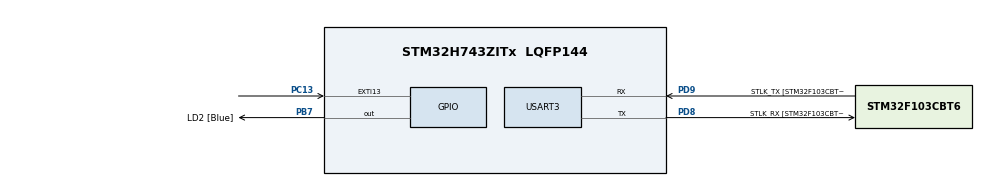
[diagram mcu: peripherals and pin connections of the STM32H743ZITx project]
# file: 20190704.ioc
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Mcu.Family=STM32H7
Mcu.Name=STM32H743ZITx
Mcu.Package=LQFP144
NVIC.EXTI15_10_IRQn=true\:1\:0\:true\:false\:true\:true\:true
NVIC.PriorityGroup=NVIC_PRIORITYGROUP_4
NVIC.TIM3_IRQn=true\:2\:0\:true\:false\:true\:true\:true
PA13\ (JTMS/SWDIO).Mode=Serial_Wire
PA13\ (JTMS/SWDIO).Signal=DEBUG_JTMS-SWDIO
PA14\ (JTCK/SWCLK).Mode=Serial_Wire
PA14\ (JTCK/SWCLK).Signal=DEBUG_JTCK-SWCLK
PB7.GPIO_Label=LD2 [Blue]
PB7.Signal=GPIO_Output
PC13.Signal=GPXTI13
PC14-OSC32_IN\ (OSC32_IN).Mode=LSE-External-Oscillator
PC14-OSC32_IN\ (OSC32_IN).Signal=RCC_OSC32_IN
PC15-OSC32_OUT\ (OSC32_OUT).Mode=LSE-External-Oscillator
PC15-OSC32_OUT\ (OSC32_OUT).Signal=RCC_OSC32_OUT
PD8.GPIO_Label=STLK_RX [STM32F103CBT6_PA3]
PD8.Mode=Asynchronous
PD8.Signal=USART3_TX
PD9.GPIO_Label=STLK_TX [STM32F103CBT6_PA2]
PD9.Mode=Asynchronous
PD9.Signal=USART3_RX
PH0-OSC_IN\ (PH0).GPIO_Label=MCO
PH0-OSC_IN\ (PH0).Mode=HSE-External-Clock-Source
PH0-OSC_IN\ (PH0).Signal=RCC_OSC_IN
PH1-OSC_OUT\ (PH1).Mode=HSE-External-Clock-Source
PH1-OSC_OUT\ (PH1).Signal=RCC_OSC_OUT
ProjectManager.HeapSize=0x200
ProjectManager.StackSize=0x400
ProjectManager.TargetToolchain=MDK-ARM V5
RCC.48MHZClocksFreq_Value=24000000
RCC.ADCFreq_Value=16125000
RCC.AHBFreq_Value=216000000
RCC.APB1CLKDivider=RCC_HCLK_DIV4
RCC.APB1Freq_Value=120000000
RCC.APB1TimFreq_Value=108000000
RCC.APB2CLKDivider=RCC_HCLK_DIV2
RCC.APB2Freq_Value=120000000
RCC.APB2TimFreq_Value=216000000
RCC.APB3Freq_Value=120000000
RCC.APB4Freq_Value=120000000
RCC.CortexFreq_Value=480000000
RCC.D1PPRE=RCC_APB3_DIV2
RCC.D2PPRE1=RCC_APB1_DIV2
RCC.D2PPRE2=RCC_APB2_DIV2
RCC.D3PPRE=RCC_APB4_DIV2
RCC.DIVM1=1
RCC.DIVN1=120
RCC.DIVQ1=20
RCC.HCLKFreq_Value=240000000
RCC.HPRE=RCC_HCLK_DIV2
RCC.HSE_VALUE=8000000
RCC.HSI_VALUE=64000000
RCC.PLLFRACN=0
RCC.PLLM=25
RCC.PLLMUL=RCC_PLL_MUL9
RCC.PLLN=432
RCC.PLLQ=9
RCC.PLLSourceVirtual=RCC_PLLSOURCE_HSE
RCC.PRESCALERUSB=RCC_USBCLKSOURCE_PLL_DIV1_5
RCC.PWR_Regulator_Voltage_Scale=PWR_REGULATOR_VOLTAGE_SCALE0
RCC.SYSCLKFreq_VALUE=480000000
RCC.SYSCLKSource=RCC_SYSCLKSOURCE_PLLCLK
RCC.SYSCLKSourceVirtual=RCC_SYSCLKSOURCE_PLLCLK
RCC.USBFreq_Value=48000000
RCC.VCOOutputFreq_Value=432000000
TIM3.Period=4000
TIM3.Prescaler=60000
USART3.VirtualMode-Asynchronous=VM_ASYNC
VP_TIM3_VS_ClockSourceINT.Mode=Internal
board=NUCLEO-H743ZI

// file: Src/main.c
/* USER CODE BEGIN Header */
/**
  ******************************************************************************
  * @file           : main.c
  * @brief          : Main program body
  ******************************************************************************
  * @attention
  *
  * <h2><center>&copy; Copyright (c) 2019 STMicroelectronics.
  * All rights reserved.</center></h2>
  *
  * This software component is licensed by ST under BSD 3-Clause license,
  * the "License"; You may not use this file except in compliance with the
  * License. You may obtain a copy of the License at:
  *                        opensource.org/licenses/BSD-3-Clause
  *
  ******************************************************************************
  */
/* USER CODE END Header */

#include "main.h"
#include "tim.h"
#include "usart.h"
#include "gpio.h"

/* USER CODE BEGIN Includes */
#include "mymain.h"
#include "stm32h7xx_hal.h"
/* USER CODE END Includes */

/* USER CODE BEGIN PM */

void HAL_GPIO_EXTI_Callback (uint16_t GPIO_Pin)
{

	if(HAL_GPIO_ReadPin(GPIOC,GPIO_PIN_13))
		{
			  HAL_GPIO_TogglePin(GPIOB ,GPIO_PIN_7);
			  HAL_Delay (100);
		}

}

void HAL_TIM_PeriodElapsedCallback (TIM_HandleTypeDef * htim)
{
	HAL_GPIO_TogglePin(GPIOB ,GPIO_PIN_7);

}

/* USER CODE END PM */

void SystemClock_Config(void);

int main(void)
{

  /* MCU Configuration--------------------------------------------------------*/

  /* Reset of all peripherals, Initializes the Flash interface and the Systick. */
  HAL_Init();

  /* Configure the system clock */
  SystemClock_Config();

  /* Initialize all configured peripherals */
  MX_GPIO_Init();
  MX_USART3_UART_Init();
  MX_TIM3_Init();

  /* Infinite loop */
  /* USER CODE BEGIN WHILE */
  while (1)
  {
		Mymain();
    /* USER CODE END WHILE */

  }
}

void SystemClock_Config(void)
{
  RCC_OscInitTypeDef RCC_OscInitStruct = {0};
  RCC_ClkInitTypeDef RCC_ClkInitStruct = {0};
  RCC_PeriphCLKInitTypeDef PeriphClkInitStruct = {0};

  /** Supply configuration update enable
  */
  HAL_PWREx_ConfigSupply(PWR_LDO_SUPPLY);
  /** Configure the main internal regulator output voltage
  */
  __HAL_PWR_VOLTAGESCALING_CONFIG(PWR_REGULATOR_VOLTAGE_SCALE0);

  while(!__HAL_PWR_GET_FLAG(PWR_FLAG_VOSRDY)) {}
  /** Initializes the CPU, AHB and APB busses clocks
  */
  RCC_OscInitStruct.OscillatorType = RCC_OSCILLATORTYPE_HSE;
  RCC_OscInitStruct.HSEState = RCC_HSE_BYPASS;
  RCC_OscInitStruct.PLL.PLLState = RCC_PLL_ON;
  RCC_OscInitStruct.PLL.PLLSource = RCC_PLLSOURCE_HSE;
  RCC_OscInitStruct.PLL.PLLM = 1;
  RCC_OscInitStruct.PLL.PLLN = 120;
  RCC_OscInitStruct.PLL.PLLP = 2;
  RCC_OscInitStruct.PLL.PLLQ = 20;
  RCC_OscInitStruct.PLL.PLLR = 2;
  RCC_OscInitStruct.PLL.PLLRGE = RCC_PLL1VCIRANGE_3;
  RCC_OscInitStruct.PLL.PLLVCOSEL = RCC_PLL1VCOWIDE;
  RCC_OscInitStruct.PLL.PLLFRACN = 0;
  if (HAL_RCC_OscConfig(&RCC_OscInitStruct) != HAL_OK)
  {
    Error_Handler();
  }
  /** Initializes the CPU, AHB and APB busses clocks
  */
  RCC_ClkInitStruct.ClockType = RCC_CLOCKTYPE_HCLK|RCC_CLOCKTYPE_SYSCLK
                              |RCC_CLOCKTYPE_PCLK1|RCC_CLOCKTYPE_PCLK2
                              |RCC_CLOCKTYPE_D3PCLK1|RCC_CLOCKTYPE_D1PCLK1;
  RCC_ClkInitStruct.SYSCLKSource = RCC_SYSCLKSOURCE_PLLCLK;
  RCC_ClkInitStruct.SYSCLKDivider = RCC_SYSCLK_DIV1;
  RCC_ClkInitStruct.AHBCLKDivider = RCC_HCLK_DIV2;
  RCC_ClkInitStruct.APB3CLKDivider = RCC_APB3_DIV2;
  RCC_ClkInitStruct.APB1CLKDivider = RCC_APB1_DIV2;
  RCC_ClkInitStruct.APB2CLKDivider = RCC_APB2_DIV2;
  RCC_ClkInitStruct.APB4CLKDivider = RCC_APB4_DIV2;

  if (HAL_RCC_ClockConfig(&RCC_ClkInitStruct, FLASH_LATENCY_4) != HAL_OK)
  {
    Error_Handler();
  }
  PeriphClkInitStruct.PeriphClockSelection = RCC_PERIPHCLK_USART3;
  PeriphClkInitStruct.Usart234578ClockSelection = RCC_USART234578CLKSOURCE_D2PCLK1;
  if (HAL_RCCEx_PeriphCLKConfig(&PeriphClkInitStruct) != HAL_OK)
  {
    Error_Handler();
  }
}

void Error_Handler(void)
{
}

/************************ (C) COPYRIGHT STMicroelectronics *****END OF FILE****/
